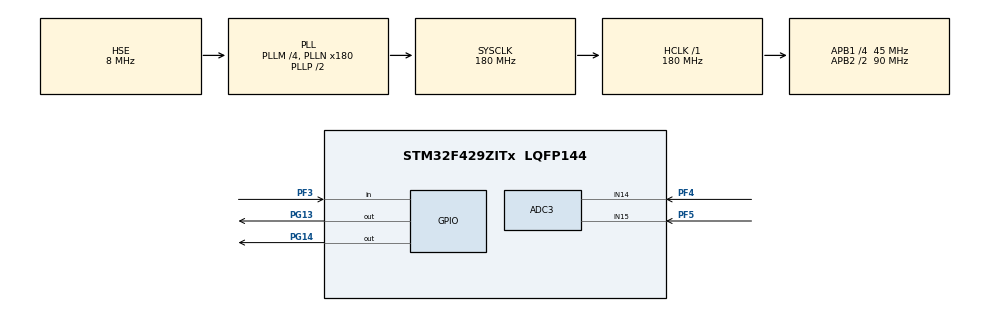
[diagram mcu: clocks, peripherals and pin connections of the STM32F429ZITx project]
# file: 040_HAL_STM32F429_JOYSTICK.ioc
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ADC3.Channel-0\#ChannelRegularConversion=ADC_CHANNEL_14
ADC3.Channel-1\#ChannelRegularConversion=ADC_CHANNEL_15
ADC3.ContinuousConvMode=ENABLE
ADC3.NbrOfConversion=2
ADC3.NbrOfConversionFlag=1
ADC3.Rank-0\#ChannelRegularConversion=1
ADC3.Rank-1\#ChannelRegularConversion=2
ADC3.SamplingTime-0\#ChannelRegularConversion=ADC_SAMPLETIME_144CYCLES
ADC3.SamplingTime-1\#ChannelRegularConversion=ADC_SAMPLETIME_144CYCLES
ADC3.ScanConvMode=ENABLE
Dma.ADC3.0.Direction=DMA_PERIPH_TO_MEMORY
Dma.ADC3.0.FIFOMode=DMA_FIFOMODE_DISABLE
Dma.ADC3.0.Instance=DMA2_Stream1
Dma.ADC3.0.MemDataAlignment=DMA_MDATAALIGN_HALFWORD
Dma.ADC3.0.MemInc=DMA_MINC_ENABLE
Dma.ADC3.0.Mode=DMA_CIRCULAR
Dma.ADC3.0.PeriphDataAlignment=DMA_PDATAALIGN_HALFWORD
Dma.ADC3.0.PeriphInc=DMA_PINC_DISABLE
Dma.ADC3.0.Priority=DMA_PRIORITY_LOW
Dma.Request0=ADC3
Mcu.Family=STM32F4
Mcu.Name=STM32F429ZITx
Mcu.Package=LQFP144
NVIC.DMA2_Stream1_IRQn=true\:0\:0\:false\:false\:true\:false\:true\:true
NVIC.PriorityGroup=NVIC_PRIORITYGROUP_0
PA13.Mode=Serial_Wire
PA13.Signal=SYS_JTMS-SWDIO
PA14.Mode=Serial_Wire
PA14.Signal=SYS_JTCK-SWCLK
PF3.Signal=GPIO_Input
PF4.Mode=IN14
PF4.Signal=ADC3_IN14
PF5.Mode=IN15
PF5.Signal=ADC3_IN15
PG13.Signal=GPIO_Output
PG14.Signal=GPIO_Output
PH0/OSC_IN.Mode=HSE-External-Oscillator
PH0/OSC_IN.Signal=RCC_OSC_IN
PH1/OSC_OUT.Mode=HSE-External-Oscillator
PH1/OSC_OUT.Signal=RCC_OSC_OUT
ProjectManager.HeapSize=0x200
ProjectManager.StackSize=0x400
ProjectManager.TargetToolchain=STM32CubeIDE
RCC.48MHZClocksFreq_Value=51428571.428571425
RCC.AHBFreq_Value=180000000
RCC.APB1CLKDivider=RCC_HCLK_DIV4
RCC.APB1Freq_Value=45000000
RCC.APB1TimFreq_Value=90000000
RCC.APB2CLKDivider=RCC_HCLK_DIV2
RCC.APB2Freq_Value=90000000
RCC.APB2TimFreq_Value=180000000
RCC.CortexFreq_Value=180000000
RCC.HCLKFreq_Value=180000000
RCC.HSE_VALUE=8000000
RCC.HSI_VALUE=16000000
RCC.LSE_VALUE=32768
RCC.PLLM=4
RCC.PLLN=180
RCC.PLLQ=7
RCC.PLLSourceVirtual=RCC_PLLSOURCE_HSE
RCC.SYSCLKFreq_VALUE=180000000
RCC.SYSCLKSource=RCC_SYSCLKSOURCE_PLLCLK
RCC.VCOOutputFreq_Value=360000000
board=STM32F429I-DISC1

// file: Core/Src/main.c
/* USER CODE BEGIN Header */
/**
  ******************************************************************************
  * @file           : main.c
  * @brief          : Main program body
  ******************************************************************************
  * @attention
  *
  * Copyright (c) 2023 STMicroelectronics.
  * All rights reserved.
  *
  * This software is licensed under terms that can be found in the LICENSE file
  * in the root directory of this software component.
  * If no LICENSE file comes with this software, it is provided AS-IS.
  *
  ******************************************************************************
  */
/* USER CODE END Header */
#include "main.h"

ADC_HandleTypeDef hadc3;
DMA_HandleTypeDef hdma_adc3;

/* USER CODE BEGIN PV */
uint32_t joystickX, joystickY, adcValue[2];
uint8_t button;
/* USER CODE END PV */

void SystemClock_Config(void);
static void MX_GPIO_Init(void);
static void MX_DMA_Init(void);
static void MX_ADC3_Init(void);

/* USER CODE BEGIN 0 */
void HAL_ADC_ConvCpltCallback(ADC_HandleTypeDef* hadc)
{
	joystickX = adcValue[0];
	joystickY = adcValue[1];
}
/* USER CODE END 0 */

int main(void)
{

  /* MCU Configuration--------------------------------------------------------*/

  /* Reset of all peripherals, Initializes the Flash interface and the Systick. */
  HAL_Init();

  /* Configure the system clock */
  SystemClock_Config();

  /* Initialize all configured peripherals */
  MX_GPIO_Init();
  MX_DMA_Init();
  MX_ADC3_Init();
  /* USER CODE BEGIN 2 */
  HAL_ADC_Start_DMA(&hadc3, (uint32_t*)adcValue, 2);
  /* USER CODE END 2 */

  /* Infinite loop */
  /* USER CODE BEGIN WHILE */
  while (1)
  {
	  button = HAL_GPIO_ReadPin(GPIOF, GPIO_PIN_3);

	  if(button)
	  {
		  HAL_GPIO_WritePin(GPIOG, GPIO_PIN_13 | GPIO_PIN_14, GPIO_PIN_SET);
	  }
	  else
	  {
		  HAL_GPIO_WritePin(GPIOG, GPIO_PIN_13 | GPIO_PIN_14, GPIO_PIN_RESET);
	  }
	  HAL_Delay(200);
    /* USER CODE END WHILE */

  }
}

void SystemClock_Config(void)
{
  RCC_OscInitTypeDef RCC_OscInitStruct = {0};
  RCC_ClkInitTypeDef RCC_ClkInitStruct = {0};

  /** Configure the main internal regulator output voltage
  */
  __HAL_RCC_PWR_CLK_ENABLE();
  __HAL_PWR_VOLTAGESCALING_CONFIG(PWR_REGULATOR_VOLTAGE_SCALE1);

  /** Initializes the RCC Oscillators according to the specified parameters
  * in the RCC_OscInitTypeDef structure.
  */
  RCC_OscInitStruct.OscillatorType = RCC_OSCILLATORTYPE_HSE;
  RCC_OscInitStruct.HSEState = RCC_HSE_ON;
  RCC_OscInitStruct.PLL.PLLState = RCC_PLL_ON;
  RCC_OscInitStruct.PLL.PLLSource = RCC_PLLSOURCE_HSE;
  RCC_OscInitStruct.PLL.PLLM = 4;
  RCC_OscInitStruct.PLL.PLLN = 180;
  RCC_OscInitStruct.PLL.PLLP = RCC_PLLP_DIV2;
  RCC_OscInitStruct.PLL.PLLQ = 7;
  if (HAL_RCC_OscConfig(&RCC_OscInitStruct) != HAL_OK)
  {
    Error_Handler();
  }

  /** Activate the Over-Drive mode
  */
  if (HAL_PWREx_EnableOverDrive() != HAL_OK)
  {
    Error_Handler();
  }

  /** Initializes the CPU, AHB and APB buses clocks
  */
  RCC_ClkInitStruct.ClockType = RCC_CLOCKTYPE_HCLK|RCC_CLOCKTYPE_SYSCLK
                              |RCC_CLOCKTYPE_PCLK1|RCC_CLOCKTYPE_PCLK2;
  RCC_ClkInitStruct.SYSCLKSource = RCC_SYSCLKSOURCE_PLLCLK;
  RCC_ClkInitStruct.AHBCLKDivider = RCC_SYSCLK_DIV1;
  RCC_ClkInitStruct.APB1CLKDivider = RCC_HCLK_DIV4;
  RCC_ClkInitStruct.APB2CLKDivider = RCC_HCLK_DIV2;

  if (HAL_RCC_ClockConfig(&RCC_ClkInitStruct, FLASH_LATENCY_5) != HAL_OK)
  {
    Error_Handler();
  }
}

static void MX_ADC3_Init(void)
{

  ADC_ChannelConfTypeDef sConfig = {0};

  /** Configure the global features of the ADC (Clock, Resolution, Data Alignment and number of conversion)
  */
  hadc3.Instance = ADC3;
  hadc3.Init.ClockPrescaler = ADC_CLOCK_SYNC_PCLK_DIV4;
  hadc3.Init.Resolution = ADC_RESOLUTION_12B;
  hadc3.Init.ScanConvMode = ENABLE;
  hadc3.Init.ContinuousConvMode = ENABLE;
  hadc3.Init.DiscontinuousConvMode = DISABLE;
  hadc3.Init.ExternalTrigConvEdge = ADC_EXTERNALTRIGCONVEDGE_NONE;
  hadc3.Init.ExternalTrigConv = ADC_SOFTWARE_START;
  hadc3.Init.DataAlign = ADC_DATAALIGN_RIGHT;
  hadc3.Init.NbrOfConversion = 2;
  hadc3.Init.DMAContinuousRequests = DISABLE;
  hadc3.Init.EOCSelection = ADC_EOC_SINGLE_CONV;
  if (HAL_ADC_Init(&hadc3) != HAL_OK)
  {
    Error_Handler();
  }

  /** Configure for the selected ADC regular channel its corresponding rank in the sequencer and its sample time.
  */
  sConfig.Channel = ADC_CHANNEL_14;
  sConfig.Rank = 1;
  sConfig.SamplingTime = ADC_SAMPLETIME_144CYCLES;
  if (HAL_ADC_ConfigChannel(&hadc3, &sConfig) != HAL_OK)
  {
    Error_Handler();
  }

  /** Configure for the selected ADC regular channel its corresponding rank in the sequencer and its sample time.
  */
  sConfig.Channel = ADC_CHANNEL_15;
  sConfig.Rank = 2;
  if (HAL_ADC_ConfigChannel(&hadc3, &sConfig) != HAL_OK)
  {
    Error_Handler();
  }

}

static void MX_DMA_Init(void)
{

  /* DMA controller clock enable */
  __HAL_RCC_DMA2_CLK_ENABLE();

  /* DMA interrupt init */
  /* DMA2_Stream1_IRQn interrupt configuration */
  HAL_NVIC_SetPriority(DMA2_Stream1_IRQn, 0, 0);
  HAL_NVIC_EnableIRQ(DMA2_Stream1_IRQn);

}

static void MX_GPIO_Init(void)
{
  GPIO_InitTypeDef GPIO_InitStruct = {0};

  /* GPIO Ports Clock Enable */
  __HAL_RCC_GPIOF_CLK_ENABLE();
  __HAL_RCC_GPIOH_CLK_ENABLE();
  __HAL_RCC_GPIOA_CLK_ENABLE();
  __HAL_RCC_GPIOG_CLK_ENABLE();

  /*Configure GPIO pin Output Level */
  HAL_GPIO_WritePin(GPIOG, GPIO_PIN_13|GPIO_PIN_14, GPIO_PIN_RESET);

  /*Configure GPIO pin : PF3 */
  GPIO_InitStruct.Pin = GPIO_PIN_3;
  GPIO_InitStruct.Mode = GPIO_MODE_INPUT;
  GPIO_InitStruct.Pull = GPIO_NOPULL;
  HAL_GPIO_Init(GPIOF, &GPIO_InitStruct);

  /*Configure GPIO pins : PG13 PG14 */
  GPIO_InitStruct.Pin = GPIO_PIN_13|GPIO_PIN_14;
  GPIO_InitStruct.Mode = GPIO_MODE_OUTPUT_PP;
  GPIO_InitStruct.Pull = GPIO_NOPULL;
  GPIO_InitStruct.Speed = GPIO_SPEED_FREQ_LOW;
  HAL_GPIO_Init(GPIOG, &GPIO_InitStruct);

}

void Error_Handler(void)
{
  __disable_irq();
  while (1)
  {
  }
}
